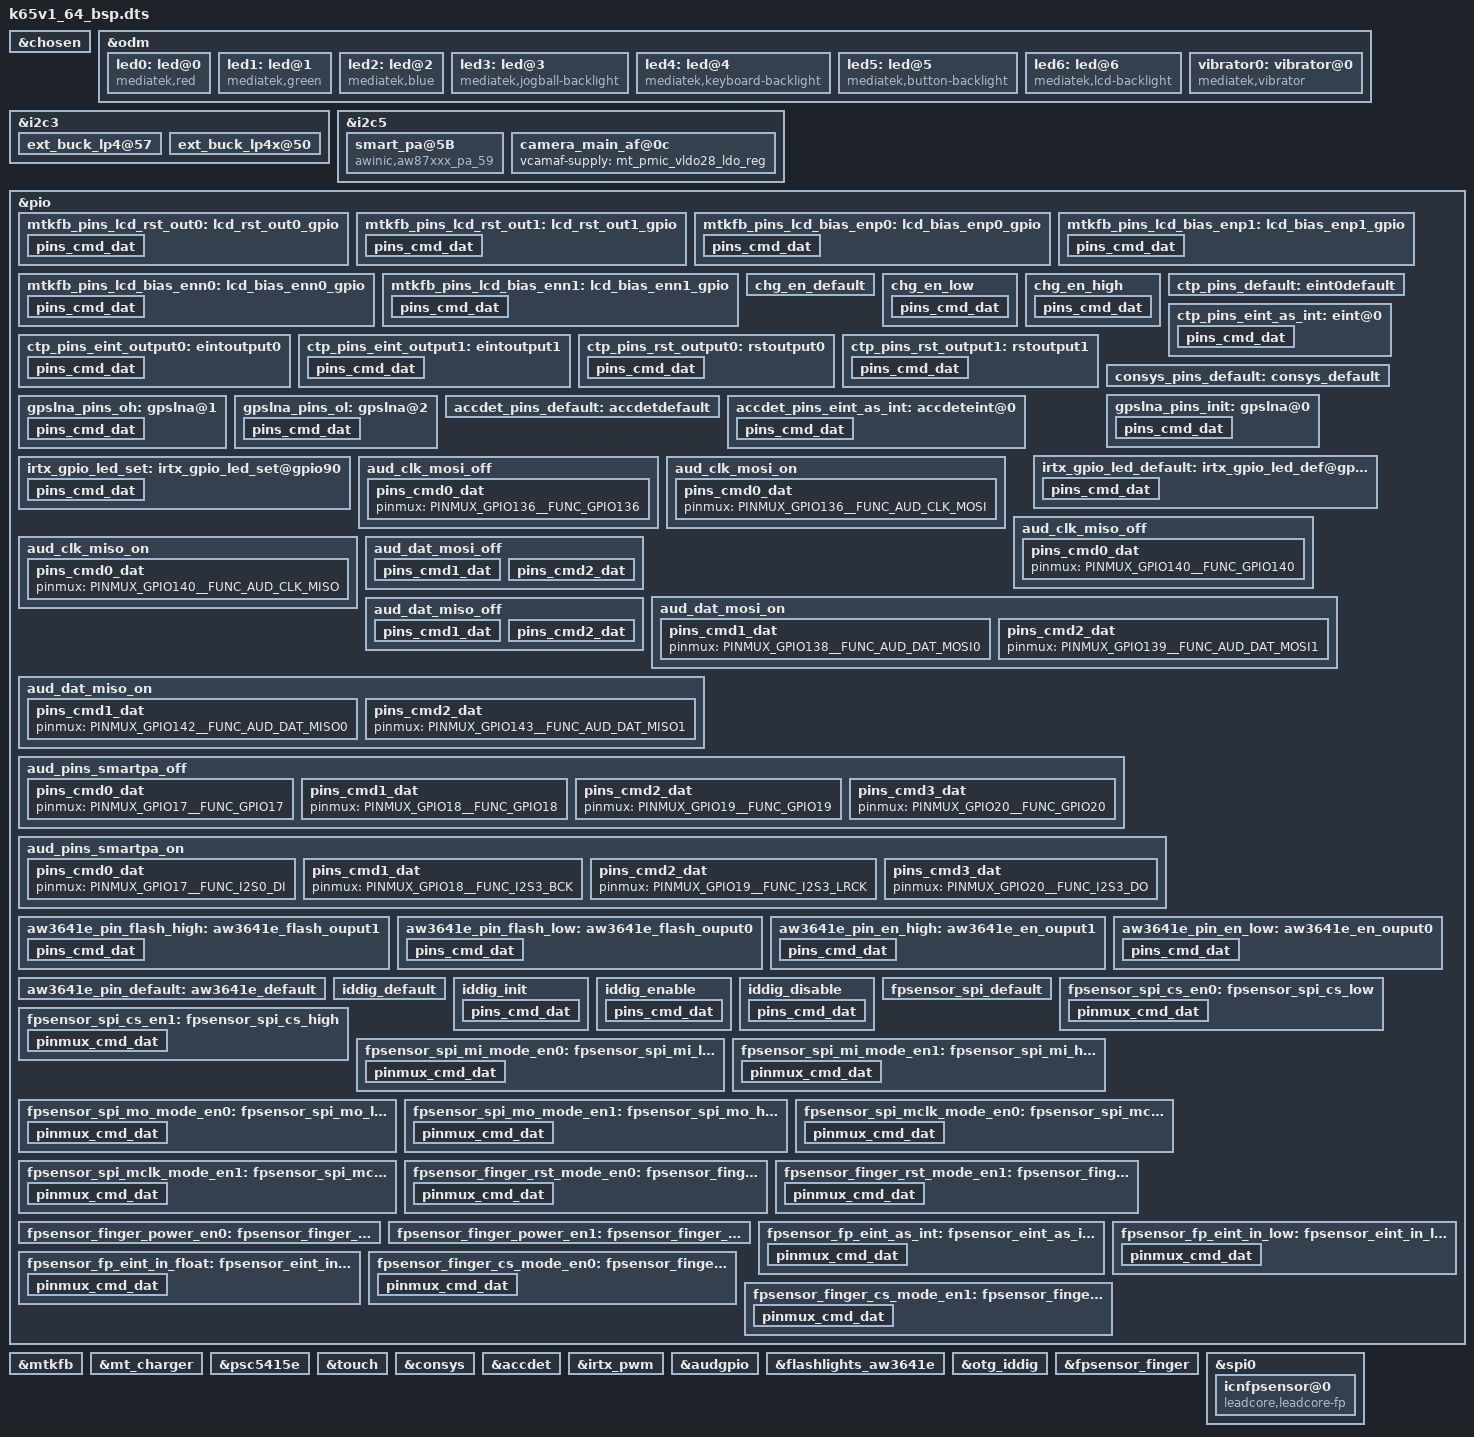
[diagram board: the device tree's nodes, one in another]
/*
 * Copyright (C) 2019 MediaTek Inc.
 *
 * This program is free software; you can redistribute it and/or modify
 * it under the terms of the GNU General Public License version 2 as
 * published by the Free Software Foundation.
 *
 * This program is distributed in the hope that it will be useful,
 * but WITHOUT ANY WARRANTY; without even the implied warranty of
 * MERCHANTABILITY or FITNESS FOR A PARTICULAR PURPOSE.
 * See http://www.gnu.org/licenses/gpl-2.0.html for more details.
 */

#include <dt-bindings/interrupt-controller/arm-gic.h>
#include <dt-bindings/interrupt-controller/irq.h>
#include <dt-bindings/pinctrl/mt6765-pinfunc.h>
#include <dt-bindings/clock/mt6765-clk.h>

/dts-v1/;
/plugin/;

/* chosen */
&chosen {

	/* fpga may has no lk, we need to specify display info here */
	/* fb buffer is reserved using this dts by memory node above */
	atag,videolfb-fb_base_h = <0x0>;
	atag,videolfb-fb_base_l = <0x5e605000>;
	atag,videolfb-islcmfound = <1>;
	/* because no lk, so lcm is not inited */
	atag,videolfb-islcm_inited = <0>;
	atag,videolfb-fps= <6000>;
	atag,videolfb-vramSize= <0x017bb000>;
	atag,videolfb-lcmname= "nt35695B_fhd_dsi_cmd_auo_rt5081_drv";
};

&odm {
	led0:led@0 {
		compatible = "mediatek,red";
		led_mode = <0>;
		data = <1>;
		pwm_config = <0 0 0 0 0>;
	};
	led1:led@1 {
		compatible = "mediatek,green";
		led_mode = <0>;
		data = <1>;
		pwm_config = <0 0 0 0 0>;
	};
	led2:led@2 {
		compatible = "mediatek,blue";
		led_mode = <0>;
		data = <1>;
		pwm_config = <0 0 0 0 0>;
	};
	led3:led@3 {
		compatible = "mediatek,jogball-backlight";
		led_mode = <0>;
		data = <1>;
		pwm_config = <0 0 0 0 0>;
	};
	led4:led@4 {
		compatible = "mediatek,keyboard-backlight";
		led_mode = <0>;
		data = <1>;
		pwm_config = <0 0 0 0 0>;
	};
	led5:led@5 {
		compatible = "mediatek,button-backlight";
		led_mode = <0>;
		data = <1>;
		pwm_config = <0 0 0 0 0>;
	};
	led6:led@6 {
		compatible = "mediatek,lcd-backlight";
		led_mode = <5>;
		data = <1>;
		pwm_config = <0 3 0 0 0>;
	};
	vibrator0:vibrator@0 {
		compatible = "mediatek,vibrator";
		vib_timer = <25>;
		vib_limit = <9>;
		vib_vol= <9>;
	};
};

&i2c3 {
	ext_buck_lp4@57 {
		regulator-name ="ext_buck_vdd2";
		regulator-min-microvolt = <300000>;
		regulator-max-microvolt = <1300000>;
		vsel_pin = <0>;
	};

	ext_buck_lp4x@50 {
		regulator-name ="ext_buck_vddq";
		regulator-min-microvolt = <300000>;
		regulator-max-microvolt = <1300000>;
		vsel_pin = <1>;
	};
};

&i2c5 {
	smart_pa@5B {
		compatible = "awinic,aw87xxx_pa_59";
		reg = <0x5b>;
		reset-gpio = <&pio 154 0>;
		monitor-flag = <1>;
		driver-num = < 0 >;
		monitor-timer-val = <3000>;
		monitor-timer-count-max = <5>;
		status = "okay";
	};

	camera_main_af@0c {
		vcamaf-supply = <&mt_pmic_vldo28_ldo_reg>;
		status = "okay";
	};
};

&pio {
	mtkfb_pins_lcd_rst_out0: lcd_rst_out0_gpio {
		pins_cmd_dat {
			pinmux = <PINMUX_GPIO45__FUNC_GPIO45>;
			slew-rate = <1>;
			output-low;
		};
	};

	mtkfb_pins_lcd_rst_out1: lcd_rst_out1_gpio {
		pins_cmd_dat {
			pinmux = <PINMUX_GPIO45__FUNC_GPIO45>;
			slew-rate = <1>;
			output-high;
		};
	};

	mtkfb_pins_lcd_bias_enp0: lcd_bias_enp0_gpio {
		pins_cmd_dat {
			pinmux = <PINMUX_GPIO65__FUNC_GPIO65>;
			slew-rate = <1>;
			output-low;
		};
	};

	mtkfb_pins_lcd_bias_enp1: lcd_bias_enp1_gpio {
		pins_cmd_dat {
			pinmux = <PINMUX_GPIO65__FUNC_GPIO65>;
			slew-rate = <1>;
			output-high;
		};
	};

	mtkfb_pins_lcd_bias_enn0: lcd_bias_enn0_gpio {
		pins_cmd_dat {
			pinmux = <PINMUX_GPIO66__FUNC_GPIO66>;
			slew-rate = <1>;
			output-low;
		};
	};

	mtkfb_pins_lcd_bias_enn1: lcd_bias_enn1_gpio {
		pins_cmd_dat {
			pinmux = <PINMUX_GPIO66__FUNC_GPIO66>;
			slew-rate = <1>;
			output-high;
		};
	};
};

&mtkfb {
	pinctrl-names = "lcm_rst_out0_gpio", "lcm_rst_out1_gpio", "lcd_bias_enp0_gpio", "lcd_bias_enp1_gpio", "lcd_bias_enn0_gpio", "lcd_bias_enn1_gpio";
	pinctrl-0 = <&mtkfb_pins_lcd_rst_out0>;
	pinctrl-1 = <&mtkfb_pins_lcd_rst_out1>;
	pinctrl-2 = <&mtkfb_pins_lcd_bias_enp0>;
	pinctrl-3 = <&mtkfb_pins_lcd_bias_enp1>;
	pinctrl-4 = <&mtkfb_pins_lcd_bias_enn0>;
	pinctrl-5 = <&mtkfb_pins_lcd_bias_enn1>;
	status = "okay";
};

&mt_charger {
	status = "okay";
};

&psc5415e {
	charger_name = "primary_chg";
	alias_name = "psc5415e";
	pinctrl-names = "default","psc_chg_en_low","psc_chg_en_high";
	pinctrl-0 = <&chg_en_default>;
	pinctrl-1 = <&chg_en_low>;
	pinctrl-2 = <&chg_en_high>;
	status = "okay";
};

&pio {
	chg_en_default: chg_en_default {
	};

	chg_en_low: chg_en_low {
		pins_cmd_dat {
			pinmux = <PINMUX_GPIO13__FUNC_GPIO13>;
			slew-rate = <1>;
			bias-disable;
			output-low;
		};
	};

	chg_en_high: chg_en_high {
		pins_cmd_dat {
			pinmux = <PINMUX_GPIO13__FUNC_GPIO13>;
			slew-rate = <1>;
			bias-disable;
			output-high;
		};
	};
};

/* TOUCH start */
&touch {
	tpd-resolution = <720 1600>;
	use-tpd-button = <0>;
	tpd-key-num = <3>;
	tpd-key-local= <139 172 158 0>;
	tpd-key-dim-local = <90 883 100 40 230
				 883 100 40 370 883 100 40 0 0 0 0>;
	tpd-max-touch-num = <5>;
	tpd-filter-enable = <1>;
	tpd-filter-pixel-density = <146>;
	tpd-filter-custom-prameters = <0 0 0 0 0 0 0 0 0 0 0 0>;
	tpd-filter-custom-speed = <0 0 0>;
	pinctrl-names = "default", "state_eint_as_int", "state_eint_output0",
		"state_eint_output1", "state_rst_output0", "state_rst_output1";
	pinctrl-0 = <&ctp_pins_default>;
	pinctrl-1 = <&ctp_pins_eint_as_int>;
	pinctrl-2 = <&ctp_pins_eint_output0>;
	pinctrl-3 = <&ctp_pins_eint_output1>;
	pinctrl-4 = <&ctp_pins_rst_output0>;
	pinctrl-5 = <&ctp_pins_rst_output1>;
	status = "okay";
};
&pio {
	ctp_pins_default: eint0default {
	};
	ctp_pins_eint_as_int: eint@0 {
		pins_cmd_dat {
			pinmux = <PINMUX_GPIO20__FUNC_GPIO20>;
			slew-rate = <0>;
			bias-disable;
		};
	};
	ctp_pins_eint_output0: eintoutput0 {
		pins_cmd_dat {
			pinmux = <PINMUX_GPIO20__FUNC_GPIO20>;
			slew-rate = <1>;
			output-low;
		};
	};
	ctp_pins_eint_output1: eintoutput1 {
		pins_cmd_dat {
			pinmux = <PINMUX_GPIO20__FUNC_GPIO20>;
			slew-rate = <1>;
			output-high;
		};
	};
	ctp_pins_rst_output0: rstoutput0 {
		pins_cmd_dat {
			pinmux = <PINMUX_GPIO174__FUNC_GPIO174>;
			slew-rate = <1>;
			output-low;
		};
	};
	ctp_pins_rst_output1: rstoutput1 {
		pins_cmd_dat {
			pinmux = <PINMUX_GPIO174__FUNC_GPIO174>;
			slew-rate = <1>;
			output-high;
		};
	};
};
/* TOUCH end */

/* CONSYS GPIO standardization */
&pio {
	consys_pins_default: consys_default {
	};
	gpslna_pins_init: gpslna@0 {
		pins_cmd_dat {
			pinmux = <PINMUX_GPIO91__FUNC_GPIO91>;
			slew-rate = <0>;
			bias-disable;
			output-low;
		};
	};
	gpslna_pins_oh: gpslna@1 {
		pins_cmd_dat {
			pinmux = <PINMUX_GPIO91__FUNC_GPIO91>;
			slew-rate = <1>;
			output-high;
		};
	};
	gpslna_pins_ol: gpslna@2 {
		pins_cmd_dat {
			pinmux = <PINMUX_GPIO91__FUNC_GPIO91>;
			slew-rate = <1>;
			output-low;
		};
	};
};
&consys {
	pinctrl-names = "default", "gps_lna_state_init",
		"gps_lna_state_oh", "gps_lna_state_ol";
	pinctrl-0 = <&consys_pins_default>;
	pinctrl-1 = <&gpslna_pins_init>;
	pinctrl-2 = <&gpslna_pins_oh>;
	pinctrl-3 = <&gpslna_pins_ol>;
	status = "okay";
};
/* CONSYS end */

/* accdet start */
&accdet {
	accdet-mic-vol = <6>;
	headset-mode-setting = <0x500 0x500 1 0x1f0 0x800 0x800 0x20 0x44>;
	accdet-plugout-debounce = <1>;
	accdet-mic-mode = <1>;
	headset-eint-level-pol = <8>;
	headset-three-key-threshold = <0 80 220 400>;
	headset-three-key-threshold-CDD = <0 121 192 600>;
	headset-four-key-threshold = <0 58 121 192 400>;
	pinctrl-names = "default", "state_eint_as_int";
	pinctrl-0 = <&accdet_pins_default>;
	pinctrl-1 = <&accdet_pins_eint_as_int>;
	status = "okay";
};
&pio {
	accdet_pins_default: accdetdefault {
	};
	accdet_pins_eint_as_int: accdeteint@0 {
		pins_cmd_dat {
			pinmux = <PINMUX_GPIO9__FUNC_GPIO9>;
			slew-rate = <0>;
			bias-disable;
		};
	};
};
/* accdet end */

/* IRTX GPIO end */
&irtx_pwm {
	pinctrl-names = "irtx_gpio_led_default", "irtx_gpio_led_set";
	pinctrl-0 = <&irtx_gpio_led_default>;
	pinctrl-1 = <&irtx_gpio_led_set>;
	status = "okay";
};
&pio {
	irtx_gpio_led_default:irtx_gpio_led_def@gpio90 {
		pins_cmd_dat {
			pinmux = <PINMUX_GPIO90__FUNC_GPIO90>;
			slew-rate = <1>;
			bias-disable;
			output-low;
			input-schmitt-enable = <0>;
		};
	};

	irtx_gpio_led_set:irtx_gpio_led_set@gpio90 {
		pins_cmd_dat {
			pinmux = <PINMUX_GPIO90__FUNC_PWM0>;
			slew-rate = <1>;
			output-high;
		};
	};
};
/* IRTX GPIO Settings -End */

/* AUDIO GPIO standardization */
&audgpio {
	pinctrl-names = "aud_clk_mosi_off",
			"aud_clk_mosi_on",
			"aud_clk_miso_off",
			"aud_clk_miso_on",
			"aud_dat_mosi_off",
			"aud_dat_mosi_on",
			"aud_dat_miso_off",
			"aud_dat_miso_on",
			"aud_smartpa_off",
			"aud_smartpa_on";
	pinctrl-0 = <&aud_clk_mosi_off>;
	pinctrl-1 = <&aud_clk_mosi_on>;
	pinctrl-2 = <&aud_clk_miso_off>;
	pinctrl-3 = <&aud_clk_miso_on>;
	pinctrl-4 = <&aud_dat_mosi_off>;
	pinctrl-5 = <&aud_dat_mosi_on>;
	pinctrl-6 = <&aud_dat_miso_off>;
	pinctrl-7 = <&aud_dat_miso_on>;
	pinctrl-8 = <&aud_pins_smartpa_off>;
	pinctrl-9 = <&aud_pins_smartpa_on>;
	status = "okay";
};

&pio {
	aud_clk_mosi_off: aud_clk_mosi_off {
		pins_cmd0_dat {
			pinmux = <PINMUX_GPIO136__FUNC_GPIO136>;
		};
	};

	aud_clk_mosi_on: aud_clk_mosi_on {
		pins_cmd0_dat {
			pinmux = <PINMUX_GPIO136__FUNC_AUD_CLK_MOSI>;
		};
	};

	aud_clk_miso_off: aud_clk_miso_off {
		pins_cmd0_dat {
			pinmux = <PINMUX_GPIO140__FUNC_GPIO140>;
		};
	};

	aud_clk_miso_on: aud_clk_miso_on {
		pins_cmd0_dat {
			pinmux = <PINMUX_GPIO140__FUNC_AUD_CLK_MISO>;
		};
	};

	aud_dat_mosi_off: aud_dat_mosi_off {
		pins_cmd1_dat {
			pinmux = <PINMUX_GPIO138__FUNC_GPIO138>;
			input-enable;
			slew-rate = <0>;
			bias-disable;
		};
		pins_cmd2_dat {
			pinmux = <PINMUX_GPIO139__FUNC_GPIO139>;
			input-enable;
			slew-rate = <0>;
			bias-disable;
		};
	};

	aud_dat_mosi_on: aud_dat_mosi_on {
		pins_cmd1_dat {
			pinmux = <PINMUX_GPIO138__FUNC_AUD_DAT_MOSI0>;
		};
		pins_cmd2_dat {
			pinmux = <PINMUX_GPIO139__FUNC_AUD_DAT_MOSI1>;
		};
	};

	aud_dat_miso_off: aud_dat_miso_off {
		pins_cmd1_dat {
			pinmux = <PINMUX_GPIO142__FUNC_GPIO142>;
			input-enable;
			slew-rate = <0>;
			bias-disable;
		};
		pins_cmd2_dat {
			pinmux = <PINMUX_GPIO143__FUNC_GPIO143>;
			input-enable;
			slew-rate = <0>;
			bias-disable;
		};
	};

	aud_dat_miso_on: aud_dat_miso_on {
		pins_cmd1_dat {
			pinmux = <PINMUX_GPIO142__FUNC_AUD_DAT_MISO0>;
		};
		pins_cmd2_dat {
			pinmux = <PINMUX_GPIO143__FUNC_AUD_DAT_MISO1>;
		};
	};

	aud_pins_smartpa_off: aud_pins_smartpa_off {
		pins_cmd0_dat {
			pinmux = <PINMUX_GPIO17__FUNC_GPIO17>;
		};
		pins_cmd1_dat {
			pinmux = <PINMUX_GPIO18__FUNC_GPIO18>;
		};
		pins_cmd2_dat {
			pinmux = <PINMUX_GPIO19__FUNC_GPIO19>;
		};
		pins_cmd3_dat {
			pinmux = <PINMUX_GPIO20__FUNC_GPIO20>;
		};
	};

	aud_pins_smartpa_on: aud_pins_smartpa_on {
		pins_cmd0_dat {
			pinmux = <PINMUX_GPIO17__FUNC_I2S0_DI>;
		};
		pins_cmd1_dat {
			pinmux = <PINMUX_GPIO18__FUNC_I2S3_BCK>;
		};
		pins_cmd2_dat {
			pinmux = <PINMUX_GPIO19__FUNC_I2S3_LRCK>;
		};
		pins_cmd3_dat {
			pinmux = <PINMUX_GPIO20__FUNC_I2S3_DO>;
		};
	};
};
/* AUDIO end */

&pio {
	aw3641e_pin_flash_high: aw3641e_flash_ouput1 {
		pins_cmd_dat {
			pinmux = <PINMUX_GPIO150__FUNC_GPIO150>;
			slew-rate = <1>;
			output-high;
		};
	};
	aw3641e_pin_flash_low: aw3641e_flash_ouput0 {
		pins_cmd_dat {
			pinmux = <PINMUX_GPIO150__FUNC_GPIO150>;
			slew-rate = <1>;
			output-low;
		};
	};
	aw3641e_pin_en_high: aw3641e_en_ouput1 {
		pins_cmd_dat {
			pinmux = <PINMUX_GPIO151__FUNC_GPIO151>;
			slew-rate = <1>;
			output-high;
		};
	};
	aw3641e_pin_en_low: aw3641e_en_ouput0 {
		pins_cmd_dat {
			pinmux = <PINMUX_GPIO151__FUNC_GPIO151>;
			slew-rate = <1>;
			output-low;
		};
	};
	aw3641e_pin_default: aw3641e_default {
	};

};

&flashlights_aw3641e {
	pinctrl-names = "default", "flash_high", "flash_low", "en_high", "en_low";
	pinctrl-0 = <&aw3641e_pin_default>;
	pinctrl-1 = <&aw3641e_pin_flash_high>;
	pinctrl-2 = <&aw3641e_pin_flash_low>;
	pinctrl-3 = <&aw3641e_pin_en_high>;
	pinctrl-4 = <&aw3641e_pin_en_low>;
	status = "okay";
};

&pio {
	iddig_default: iddig_default {
	};
	iddig_init: iddig_init {
		pins_cmd_dat {
			pinmux = <PINMUX_GPIO41__FUNC_IDDIG>;
			input-enable;
			slew-rate = <0>;
			bias-pull-up;
		};
	};
	iddig_enable: iddig_enable {
		pins_cmd_dat {
			pinmux = <PINMUX_GPIO41__FUNC_IDDIG>;
			input-enable;
			slew-rate = <0>;
			bias-pull-up;
		};
	};
	iddig_disable: iddig_disable {
		pins_cmd_dat {
			pinmux = <PINMUX_GPIO41__FUNC_GPIO41>;
			input-disable;
			slew-rate = <1>;
			output-low;
		};
	};
};

&otg_iddig {
	pinctrl-names = "iddig_default", "iddig_init",
	"iddig_enable", "iddig_disable";
	pinctrl-0 = <&iddig_default>;
	pinctrl-1 = <&iddig_init>;
	pinctrl-2 = <&iddig_enable>;
	pinctrl-3 = <&iddig_disable>;
	status = "okay";
};

&pio {
	fpsensor_spi_default: fpsensor_spi_default {
	};

	fpsensor_spi_cs_en0: fpsensor_spi_cs_low {
		pinmux_cmd_dat {
			pinmux = <PINMUX_GPIO156__FUNC_SPI0_CSB>;
			slew-rate = <1>;
			output-low;
		};
	};
	fpsensor_spi_cs_en1: fpsensor_spi_cs_high {
		pinmux_cmd_dat {
			pinmux = <PINMUX_GPIO156__FUNC_SPI0_CSB>;
			slew-rate = <1>;
			output-high;
		};
	};	
	fpsensor_spi_mi_mode_en0: fpsensor_spi_mi_low {
		pinmux_cmd_dat {
			pinmux = <PINMUX_GPIO155__FUNC_SPI0_MI>;
			slew-rate = <0>;
			bias-pull-up = <00>;
		};
	};
	fpsensor_spi_mi_mode_en1: fpsensor_spi_mi_high {
		pinmux_cmd_dat {
			pinmux = <PINMUX_GPIO155__FUNC_SPI0_MI>;
			bias-disable;
		};
	};	
	fpsensor_spi_mo_mode_en0: fpsensor_spi_mo_low {
		pinmux_cmd_dat {
			pinmux = <PINMUX_GPIO157__FUNC_SPI0_MO>;
			slew-rate = <1>;
			output-low;
		};
	};
	fpsensor_spi_mo_mode_en1: fpsensor_spi_mo_high {
		pinmux_cmd_dat {
			pinmux = <PINMUX_GPIO157__FUNC_SPI0_MO>;
			slew-rate = <1>;
			output-high;
		};
	};	
	fpsensor_spi_mclk_mode_en0: fpsensor_spi_mclk_low {
		pinmux_cmd_dat {
			pinmux = <PINMUX_GPIO158__FUNC_SPI0_CLK>;
			slew-rate = <1>;
			output-low;
		};
	};
	fpsensor_spi_mclk_mode_en1: fpsensor_spi_mclk_high {
		pinmux_cmd_dat {
			pinmux = <PINMUX_GPIO158__FUNC_SPI0_CLK>;
			slew-rate = <1>;
			output-high;
		};
	};	
	fpsensor_finger_rst_mode_en0: fpsensor_finger_rst_low {
		pinmux_cmd_dat {
			pinmux = <PINMUX_GPIO168__FUNC_GPIO168>;
			slew-rate = <1>;
			output-low;
		};
	};
	fpsensor_finger_rst_mode_en1: fpsensor_finger_rst_high {
		pinmux_cmd_dat {
			pinmux = <PINMUX_GPIO168__FUNC_GPIO168>;
			slew-rate = <1>;
			output-high;
		};
	};	
	fpsensor_finger_power_en0: fpsensor_finger_power_low {
	
	};
	fpsensor_finger_power_en1: fpsensor_finger_power_high {
		
	};	
	fpsensor_fp_eint_as_int: fpsensor_eint_as_int {
		pinmux_cmd_dat {
			pinmux = <PINMUX_GPIO3__FUNC_GPIO3>;
			slew-rate = <0>;
			bias-disable;
		};
	};
	fpsensor_fp_eint_in_low: fpsensor_eint_in_low {
		pinmux_cmd_dat {
			pinmux = <PINMUX_GPIO3__FUNC_GPIO3>;
			slew-rate = <0>;
			bias-pull-down = <00>;
		};
	};
	fpsensor_fp_eint_in_float: fpsensor_eint_in_float {
		pinmux_cmd_dat {
			pinmux = <PINMUX_GPIO3__FUNC_GPIO3>;
			slew-rate = <0>;
			bias-disable;
		};
	};
	fpsensor_finger_cs_mode_en0: fpsensor_finger_cs_low {
		pinmux_cmd_dat {
			pinmux = <PINMUX_GPIO156__FUNC_SPI0_CSB>;
			slew-rate = <1>;
			output-low;
		};
	};
	fpsensor_finger_cs_mode_en1: fpsensor_finger_cs_high {
		pinmux_cmd_dat {
			pinmux = <PINMUX_GPIO156__FUNC_SPI0_CSB>;
			slew-rate = <1>;
			output-high;
		};
	};
};

&fpsensor_finger {
	interrupt-parent = <&pio>;
	interrupts = <3 IRQ_TYPE_LEVEL_LOW 9 0>;
	debounce = <3 0>;
	pinctrl-names = "fpsensor_spi_default", "fpsensor_spi_cs_low","fpsensor_spi_cs_high","fpsensor_spi_mi_low","fpsensor_spi_mi_high",
					"fpsensor_spi_mo_low","fpsensor_spi_mo_high","fpsensor_spi_mclk_low","fpsensor_spi_mclk_high",
					"fpsensor_finger_rst_low","fpsensor_finger_rst_high","fpsensor_finger_power_low","fpsensor_finger_power_high",
					"fpsensor_eint_as_int","fpsensor_eint_in_low","fpsensor_eint_in_float","fpsensor_finger_cs_low","fpsensor_finger_cs_high";
	pinctrl-0 = <&fpsensor_spi_default>;
	pinctrl-1 = <&fpsensor_spi_cs_en0>;
	pinctrl-2 = <&fpsensor_spi_cs_en1>;
	pinctrl-3 = <&fpsensor_spi_mi_mode_en0>;
	pinctrl-4 = <&fpsensor_spi_mi_mode_en1>;
	pinctrl-5 = <&fpsensor_spi_mo_mode_en0>;
	pinctrl-6 = <&fpsensor_spi_mo_mode_en1>;
	pinctrl-7 = <&fpsensor_spi_mclk_mode_en0>;
	pinctrl-8 = <&fpsensor_spi_mclk_mode_en1>;	
	pinctrl-9 = <&fpsensor_finger_rst_mode_en0>;
	pinctrl-10 = <&fpsensor_finger_rst_mode_en1>;
	pinctrl-11 = <&fpsensor_finger_power_en0>;
	pinctrl-12 = <&fpsensor_finger_power_en1>;	
	pinctrl-13 = <&fpsensor_fp_eint_as_int>;
	pinctrl-14 = <&fpsensor_fp_eint_in_low>;
	pinctrl-15 = <&fpsensor_fp_eint_in_float>;
	pinctrl-16 = <&fpsensor_finger_cs_mode_en0>;
	pinctrl-17 = <&fpsensor_finger_cs_mode_en1>;
	status = "okay";
};

/* FINGERPRINT start */
&spi0 {
	#address-cells = <1>;
	#size-cells = <0>;
	icnfpsensor@0{	
		compatible = "leadcore,leadcore-fp";		
		reg = <0>;
		spi-max-frequency = <8000000>;	
		status = "okay";
	};
};
/* FINGERPRINT end */

#include <k65v1_64_bsp/cust.dtsi>
#include "cust_mt6765_camera.dtsi"
/*End of this file, DO NOT ADD ANYTHING HERE*/
